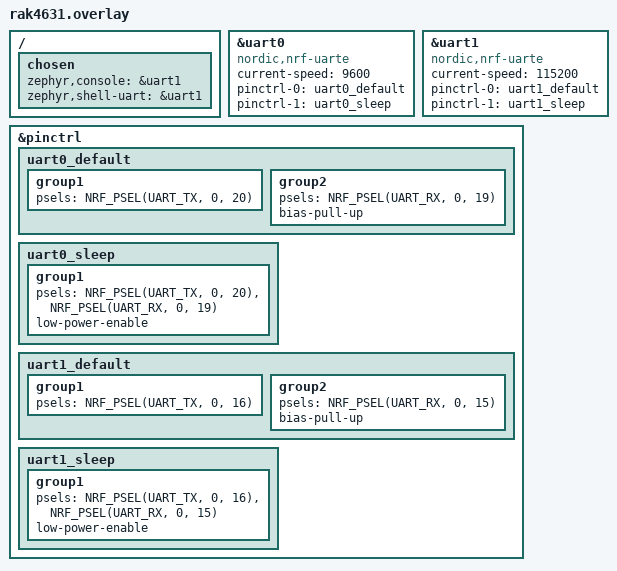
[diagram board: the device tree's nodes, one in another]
/*
 * HW Test - RS485 - RAK4631 Overlay
 * Debug UART (uart1): TX=P0.16, RX=P0.15
 * RS485 (uart0): TX=P0.20, RX=P0.19, DE=P1.04, RE#=P1.03
 */

/ {
	chosen {
		zephyr,console = &uart1;
		zephyr,shell-uart = &uart1;
	};
};

&uart0 {
	compatible = "nordic,nrf-uarte";
	status = "okay";
	current-speed = <9600>;
	pinctrl-0 = <&uart0_default>;
	pinctrl-1 = <&uart0_sleep>;
	pinctrl-names = "default", "sleep";
};

&uart1 {
	compatible = "nordic,nrf-uarte";
	status = "okay";
	current-speed = <115200>;
	pinctrl-0 = <&uart1_default>;
	pinctrl-1 = <&uart1_sleep>;
	pinctrl-names = "default", "sleep";
};

&pinctrl {
	uart0_default: uart0_default {
		group1 {
			psels = <NRF_PSEL(UART_TX, 0, 20)>;
		};
		group2 {
			psels = <NRF_PSEL(UART_RX, 0, 19)>;
			bias-pull-up;
		};
	};

	uart0_sleep: uart0_sleep {
		group1 {
			psels = <NRF_PSEL(UART_TX, 0, 20)>,
				<NRF_PSEL(UART_RX, 0, 19)>;
			low-power-enable;
		};
	};

	uart1_default: uart1_default {
		group1 {
			psels = <NRF_PSEL(UART_TX, 0, 16)>;
		};
		group2 {
			psels = <NRF_PSEL(UART_RX, 0, 15)>;
			bias-pull-up;
		};
	};

	uart1_sleep: uart1_sleep {
		group1 {
			psels = <NRF_PSEL(UART_TX, 0, 16)>,
				<NRF_PSEL(UART_RX, 0, 15)>;
			low-power-enable;
		};
	};
};
